VERSION "f33"

NS_ :

BS_:
BU_: RR RL FL FR GEN

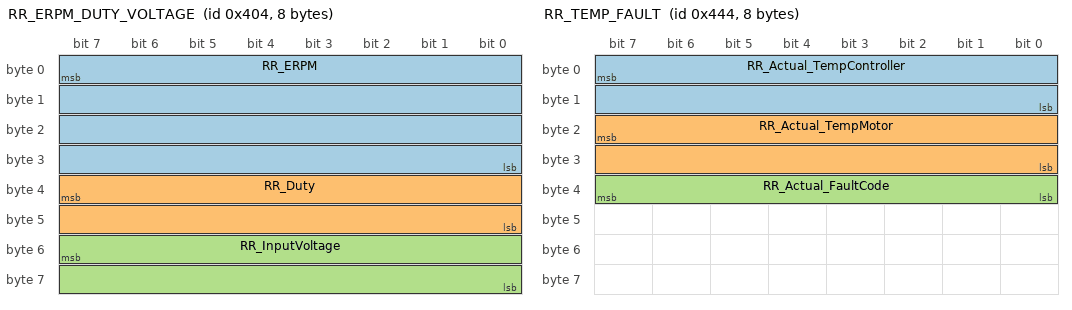
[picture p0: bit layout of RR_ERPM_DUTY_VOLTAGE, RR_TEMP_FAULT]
BO_ 1028 RR_ERPM_DUTY_VOLTAGE: 8 RR
 SG_ RR_ERPM : 7|32@0- (1,0) [-120000|120000] "rpm" Vector__XXX
 SG_ RR_Duty : 39|16@0- (0.1,0) [-100|100] "%" Vector__XXX
 SG_ RR_InputVoltage : 55|16@0- (1,0) [0|1000] "V" Vector__XXX

BO_ 1060 RR_AC_DC_CURRENT: 8 RR
 SG_ RR_AC_Current : 7|16@0- (0.1,0) [-850|850] "A"  Vector_XXX
 SG_ RR_DC_Current : 23|16@0- (0.1,0) [-850|850] "A"  Vector_XXX

BO_ 1092 RR_TEMP_FAULT: 8 RR
 SG_ RR_Actual_TempController : 7|16@0- (0.1,0) [-55|200] "C"  Vector__XXX
 SG_ RR_Actual_TempMotor : 23|16@0- (0.1,0) [-55|200] "C"  Vector__XXX
 SG_ RR_Actual_FaultCode : 39|8@0+ (1,0) [0|255] ""  Vector__XXX

BO_ 1124 RR_FOC : 8 RR
 SG_ RR_Actual_FOC_id : 7|32@0- (0.01,0) [-850|850] "Apk"  Vector__XXX
 SG_ RR_Actual_FOC_iq : 39|32@0- (0.01,0) [-850|850] "Apk"  Vector__XXX

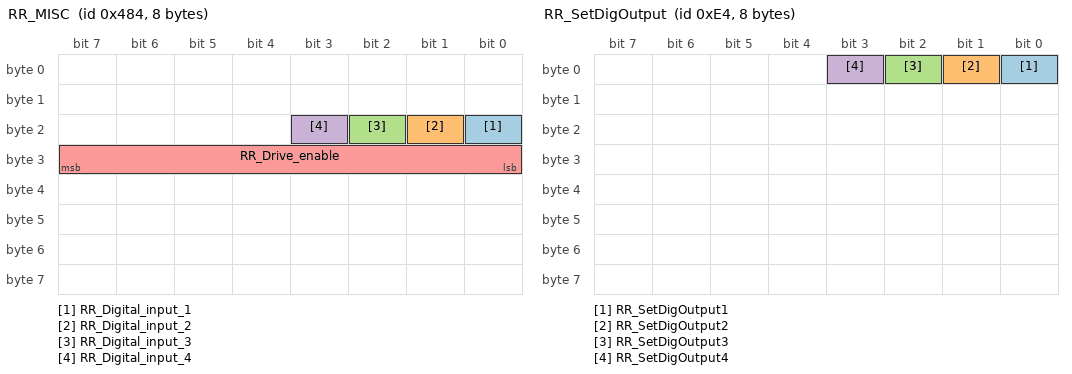
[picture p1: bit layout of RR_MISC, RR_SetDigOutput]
BO_ 1156 RR_MISC: 8 RR
 SG_ RR_Digital_input_1 : 16|1@0+ (1,0) [0|1] ""  Vector__XXX
 SG_ RR_Digital_input_2 : 17|1@0+ (1,0) [0|1] ""  Vector__XXX
 SG_ RR_Digital_input_3 : 18|1@0+ (1,0) [0|1] ""  Vector__XXX
 SG_ RR_Digital_input_4 : 19|1@0+ (1,0) [0|1] ""  Vector__XXX
 SG_ RR_Drive_enable : 31|8@0+ (1,0) [0|1] ""  Vector__XXX

BO_ 388 RR_ENABLE: 8 RR
 SG_ RR_DriveEnable : 7|8@0+ (1,0) [0|1] ""  Vector__XXX

BO_ 36 RR_SetAcCurrent: 8 RR
 SG_ RR_TargetAcCurrent : 7|16@0- (0.1,0) [-850|850] "A"  Vector__XXX

BO_ 68 RR_SetBrakeCurrent: 8 RR
 SG_ RR_TargetBrakeCurrent : 7|16@0- (0.1,0) [0|850] "A"  Vector__XXX

BO_ 100 RR_SetERPM: 4 RR
 SG_ RR_TargetSpeed : 7|32@0- (1,0) [-100000|100000] "ERPM"  Vector__XXX

BO_ 132 RR_SetPosition: 2 RR
 SG_ RR_TargetPosition : 7|16@0- (0.1,0) [0|359] "degree"  Vector__XXX

BO_ 164 RR_SetRelCurrent: 2 RR
 SG_ RR_TargetRelativeCurrent : 7|16@0- (0.1,0) [-100|100] "%"  Vector__XXX

BO_ 196 RR_SetRelBrakeCurrent: 2 RR
 SG_ RR_TargeRelativeBrakeCurrent : 7|16@0- (0.1,0) [0|100] "%"  Vector__XXX

BO_ 260 RR_SetMaxAcCurrent: 2 RR
 SG_ RR_MaxAcCurrent : 7|16@0- (0.1,0) [0|850] "A"  Vector__XXX

BO_ 292 RR_SetMaxAcBrakeCurrent: 2 RR
 SG_ RR_MaxAcBrakeCurrent : 7|16@0- (0.1,0) [-850|0] "A"  Vector__XXX

BO_ 324 RR_SetMaxDcCurrent: 2 RR
 SG_ RR_MaxDcCurrent : 7|16@0- (0.1,0) [0|850] "A"  Vector__XXX

BO_ 356 RR_SetMaxDcBrakeCurrent: 2 RR
 SG_ RR_MaxDcBrakeCurrent : 7|16@0- (0.1,0) [-850|0] "A"  Vector__XXX

BO_ 228 RR_SetDigOutput: 8 RR
 SG_ RR_SetDigOutput1 : 0|1@0+ (1,0) [0|1] "#" Vector__XXX
 SG_ RR_SetDigOutput2 : 1|1@0+ (1,0) [0|1] "#" Vector__XXX
 SG_ RR_SetDigOutput3 : 2|1@0+ (1,0) [0|1] "#" Vector__XXX
 SG_ RR_SetDigOutput4 : 3|1@0+ (1,0) [0|1] "#" Vector__XXX

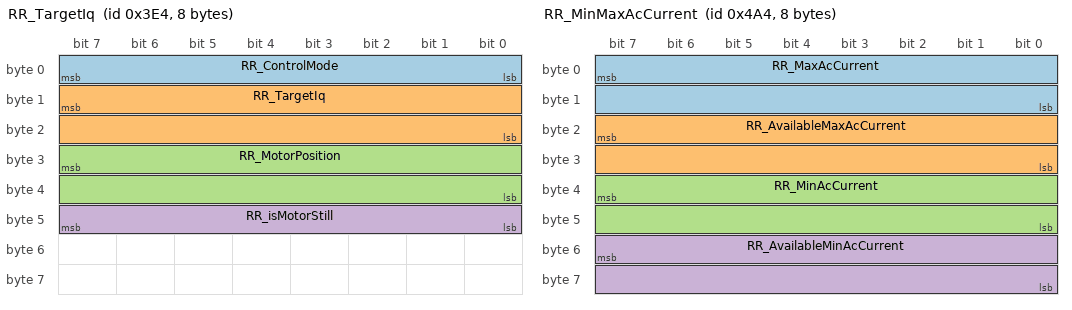
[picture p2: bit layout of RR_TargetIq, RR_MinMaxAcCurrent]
BO_ 996 RR_TargetIq: 8 RR
 SG_ RR_ControlMode : 7|8@0+ (1,0) [0|7] "#" Vector__XXX
 SG_ RR_TargetIq : 15|16@0- (0.1,0) [-850|850] "Apk" Vector__XXX
 SG_ RR_MotorPosition : 31|16@0+ (0.1,0) [0|359] "degree" Vector__XXX
 SG_ RR_isMotorStill : 47|8@0+ (1,0) [0|1] "#" Vector__XXX

BO_ 1188 RR_MinMaxAcCurrent: 8 RR
 SG_ RR_MaxAcCurrent : 7|16@0- (0.1,0) [0|850] "Apk" Vector__XXX
 SG_ RR_AvailableMaxAcCurrent : 23|16@0- (0.1,0) [0|850] "Apk" Vector__XXX
 SG_ RR_MinAcCurrent : 39|16@0- (0.1,0) [-850|0] "Apk" Vector__XXX
 SG_ RR_AvailableMinAcCurrent : 55|16@0- (0.1,0) [-850|0] "Apk" Vector__XXX

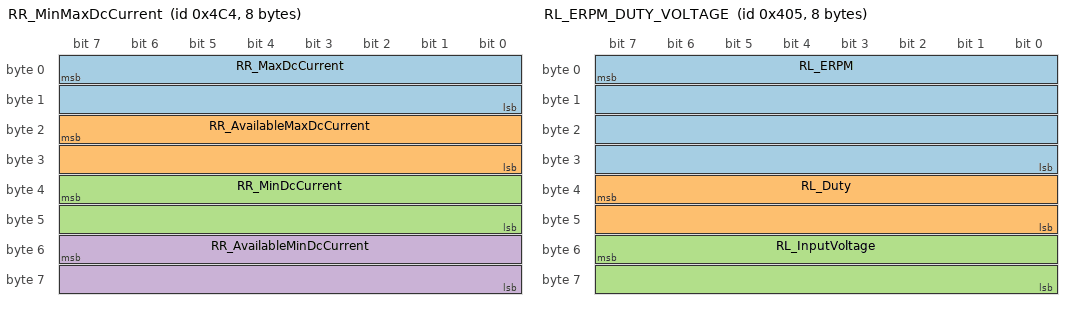
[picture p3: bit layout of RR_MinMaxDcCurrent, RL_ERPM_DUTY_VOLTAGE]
BO_ 1220 RR_MinMaxDcCurrent: 8 RR
 SG_ RR_MaxDcCurrent : 7|16@0- (0.1,0) [0|850] "Adc" Vector__XXX
 SG_ RR_AvailableMaxDcCurrent : 23|16@0- (0.1,0) [0|850] "Adc" Vector__XXX
 SG_ RR_MinDcCurrent : 39|16@0- (0.1,0) [-850|0] "Adc" Vector__XXX
 SG_ RR_AvailableMinDcCurrent : 55|16@0- (0.1,0) [-850|0] "Adc" Vector__XXX

BO_ 1029 RL_ERPM_DUTY_VOLTAGE: 8 RL
 SG_ RL_ERPM : 7|32@0- (1,0) [-120000|120000] "rpm" Vector__XXX
 SG_ RL_Duty : 39|16@0- (0.1,0) [-100|100] "%" Vector__XXX
 SG_ RL_InputVoltage : 55|16@0- (1,0) [0|1000] "V" Vector__XXX

BO_ 1061 RL_AC_DC_CURRENT: 8 RL
 SG_ RL_AC_Current : 7|16@0- (0.1,0) [-850|850] "A"  Vector_XXX
 SG_ RL_DC_Current : 23|16@0- (0.1,0) [-850|850] "A"  Vector_XXX

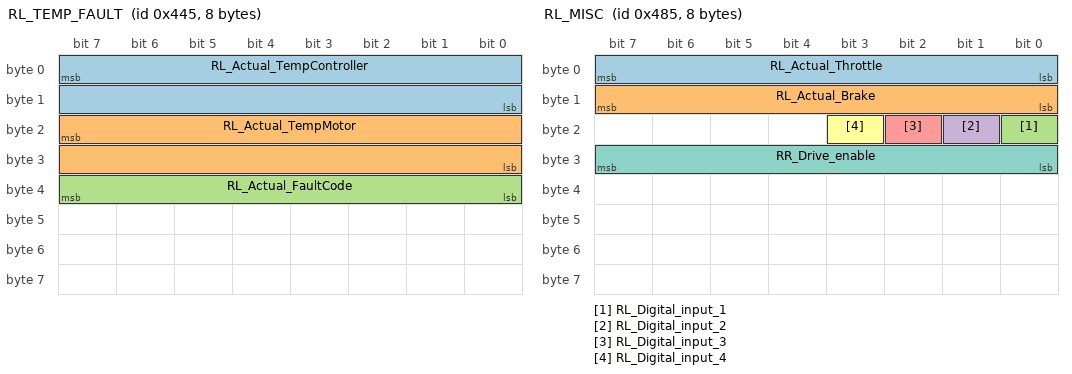
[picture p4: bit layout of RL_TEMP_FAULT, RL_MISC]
BO_ 1093 RL_TEMP_FAULT: 8 RL
 SG_ RL_Actual_TempController : 7|16@0- (0.1,0) [-55|200] "C"  Vector__XXX
 SG_ RL_Actual_TempMotor : 23|16@0- (0.1,0) [-55|200] "C"  Vector__XXX
 SG_ RL_Actual_FaultCode : 39|8@0+ (1,0) [0|255] ""  Vector__XXX

BO_ 1125 RL_FOC : 8 RL
 SG_ RL_Actual_FOC_id : 7|32@0- (0.01,0) [-850|850] "Apk"  Vector__XXX
 SG_ RL_Actual_FOC_iq : 39|32@0- (0.01,0) [-850|850] "Apk"  Vector__XXX

BO_ 1157 RL_MISC: 8 RL
 SG_ RL_Actual_Throttle : 7|8@0- (1,0) [0|100] "%"  Vector__XXX
 SG_ RL_Actual_Brake : 15|8@0- (1,0) [0|100] "%"  Vector__XXX
 SG_ RL_Digital_input_1 : 16|1@0+ (1,0) [0|1] ""  Vector__XXX
 SG_ RL_Digital_input_2 : 17|1@0+ (1,0) [0|1] ""  Vector__XXX
 SG_ RL_Digital_input_3 : 18|1@0+ (1,0) [0|1] ""  Vector__XXX
 SG_ RL_Digital_input_4 : 19|1@0+ (1,0) [0|1] ""  Vector__XXX
 SG_ RR_Drive_enable : 31|8@0+ (1,0) [0|1] ""  Vector__XXX

BO_ 389 RL_ENABLE: 8 RL
 SG_ RL_DriveEnable : 7|8@0+ (1,0) [0|1] ""  Vector__XXX

BO_ 37 RL_SetAcCurrent: 8 RL
 SG_ RL_TargetAcCurrent : 7|16@0- (0.1,0) [-850|850] "A"  Vector__XXX

BO_ 69 RL_SetBrakeCurrent: 8 RL
 SG_ RL_TargetBrakeCurrent : 7|16@0- (0.1,0) [0|850] "A"  Vector__XXX

BO_ 101 RL_SetERPM: 4 RL
 SG_ RL_TargetSpeed : 7|32@0- (1,0) [-100000|100000] "ERPM"  Vector__XXX

BO_ 133 RL_SetPosition: 2 RL
 SG_ RL_TargetPosition : 7|16@0- (0.1,0) [0|359] "degree"  Vector__XXX

BO_ 165 RL_SetRelCurrent: 2 RL
 SG_ RL_TargetRelativeCurrent : 7|16@0- (0.1,0) [-100|100] "%"  Vector__XXX

BO_ 197 RL_SetRelBrakeCurrent: 2 RL
 SG_ RL_TargeRelativeBrakeCurrent : 7|16@0- (0.1,0) [0|100] "%"  Vector__XXX

BO_ 261 RL_SetMaxAcCurrent: 2 RL
 SG_ RL_MaxAcCurrent : 7|16@0- (0.1,0) [0|850] "A"  Vector__XXX

BO_ 293 RL_SetMaxAcBrakeCurrent: 2 RL
 SG_ RL_MaxAcBrakeCurrent : 7|16@0- (0.1,0) [-850|0] "A"  Vector__XXX

BO_ 325 RL_SetMaxDcCurrent: 2 RL
 SG_ RL_MaxDcCurrent : 7|16@0- (0.1,0) [0|850] "A"  Vector__XXX

BO_ 357 RL_SetMaxDcBrakeCurrent: 2 RL
 SG_ RL_MaxDcBrakeCurrent : 7|16@0- (0.1,0) [-850|0] "A"  Vector__XXX

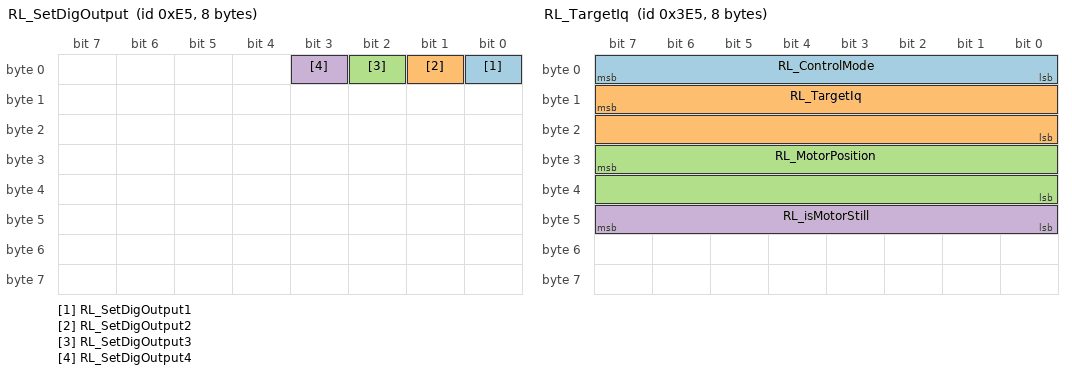
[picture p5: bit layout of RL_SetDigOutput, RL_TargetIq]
BO_ 229 RL_SetDigOutput: 8 RL
 SG_ RL_SetDigOutput1 : 0|1@0+ (1,0) [0|1] "#" Vector__XXX
 SG_ RL_SetDigOutput2 : 1|1@0+ (1,0) [0|1] "#" Vector__XXX
 SG_ RL_SetDigOutput3 : 2|1@0+ (1,0) [0|1] "#" Vector__XXX
 SG_ RL_SetDigOutput4 : 3|1@0+ (1,0) [0|1] "#" Vector__XXX

BO_ 997 RL_TargetIq: 8 RL
 SG_ RL_ControlMode : 7|8@0+ (1,0) [0|7] "#" Vector__XXX
 SG_ RL_TargetIq : 15|16@0- (0.1,0) [-850|850] "Apk" Vector__XXX
 SG_ RL_MotorPosition : 31|16@0+ (0.1,0) [0|359] "degree" Vector__XXX
 SG_ RL_isMotorStill : 47|8@0+ (1,0) [0|1] "#" Vector__XXX

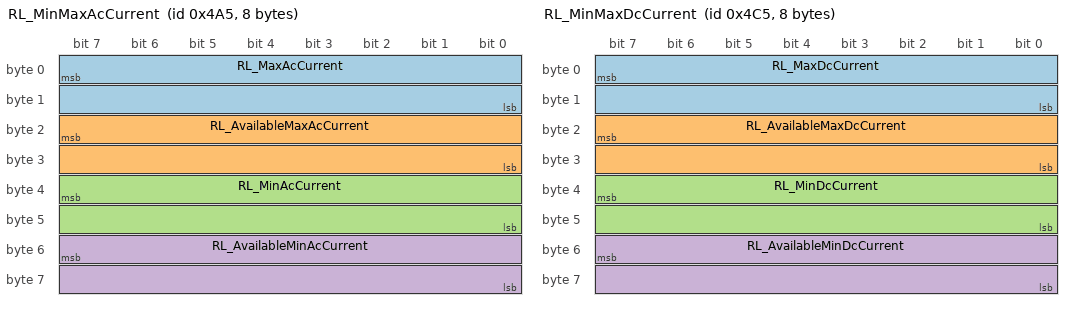
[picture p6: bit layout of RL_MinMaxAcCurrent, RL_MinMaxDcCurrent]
BO_ 1189 RL_MinMaxAcCurrent: 8 RL
 SG_ RL_MaxAcCurrent : 7|16@0- (0.1,0) [0|850] "Apk" Vector__XXX
 SG_ RL_AvailableMaxAcCurrent : 23|16@0- (0.1,0) [0|850] "Apk" Vector__XXX
 SG_ RL_MinAcCurrent : 39|16@0- (0.1,0) [-850|0] "Apk" Vector__XXX
 SG_ RL_AvailableMinAcCurrent : 55|16@0- (0.1,0) [-850|0] "Apk" Vector__XXX

BO_ 1221 RL_MinMaxDcCurrent: 8 RL
 SG_ RL_MaxDcCurrent : 7|16@0- (0.1,0) [0|850] "Adc" Vector__XXX
 SG_ RL_AvailableMaxDcCurrent : 23|16@0- (0.1,0) [0|850] "Adc" Vector__XXX
 SG_ RL_MinDcCurrent : 39|16@0- (0.1,0) [-850|0] "Adc" Vector__XXX
 SG_ RL_AvailableMinDcCurrent : 55|16@0- (0.1,0) [-850|0] "Adc" Vector__XXX

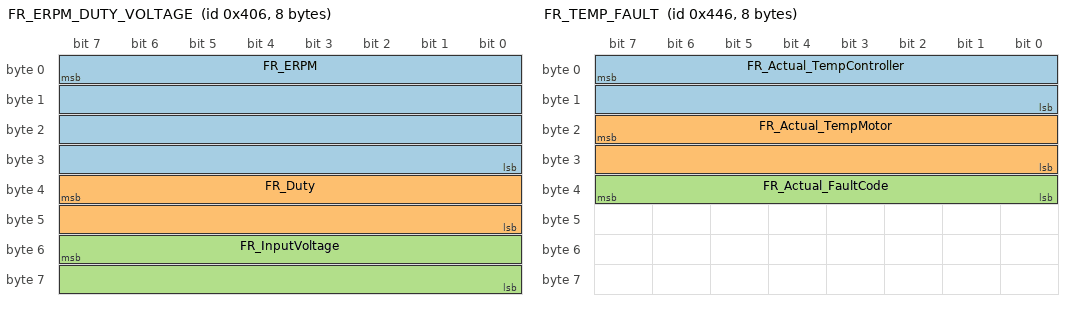
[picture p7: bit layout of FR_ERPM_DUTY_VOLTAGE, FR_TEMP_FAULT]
BO_ 1030 FR_ERPM_DUTY_VOLTAGE: 8 FR
 SG_ FR_ERPM : 7|32@0- (1,0) [-120000|120000] "rpm" Vector__XXX
 SG_ FR_Duty : 39|16@0- (0.1,0) [-100|100] "%" Vector__XXX
 SG_ FR_InputVoltage : 55|16@0- (1,0) [0|1000] "V" Vector__XXX

BO_ 1062 FR_AC_DC_CURRENT: 8 FR
 SG_ FR_AC_Current : 7|16@0- (0.1,0) [-850|850] "A"  Vector_XXX
 SG_ FR_DC_Current : 23|16@0- (0.1,0) [-850|850] "A"  Vector_XXX

BO_ 1094 FR_TEMP_FAULT: 8 FR
 SG_ FR_Actual_TempController : 7|16@0- (0.1,0) [-55|200] "C"  Vector__XXX
 SG_ FR_Actual_TempMotor : 23|16@0- (0.1,0) [-55|200] "C"  Vector__XXX
 SG_ FR_Actual_FaultCode : 39|8@0+ (1,0) [0|255] ""  Vector__XXX

BO_ 1126 FR_FOC : 8 FR
 SG_ FR_Actual_FOC_id : 7|32@0- (0.01,0) [-850|850] "Apk"  Vector__XXX
 SG_ FR_Actual_FOC_iq : 39|32@0- (0.01,0) [-850|850] "Apk"  Vector__XXX

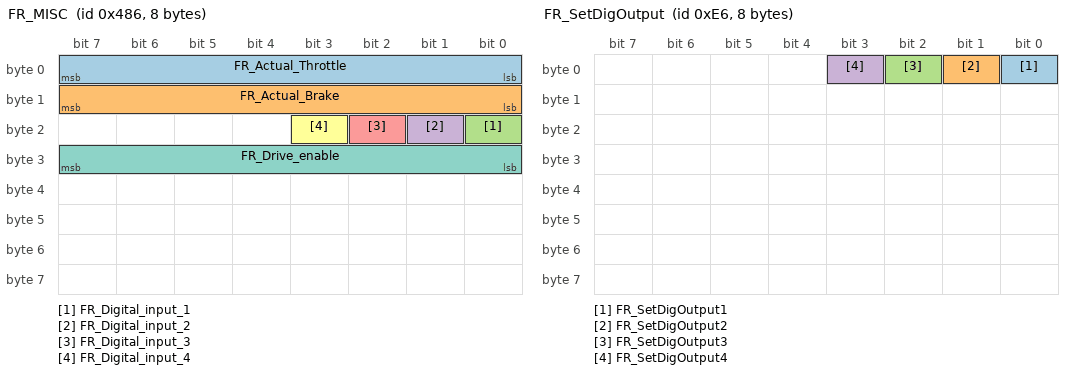
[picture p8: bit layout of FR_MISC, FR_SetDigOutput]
BO_ 1158 FR_MISC: 8 FR
 SG_ FR_Actual_Throttle : 7|8@0- (1,0) [0|100] "%"  Vector__XXX
 SG_ FR_Actual_Brake : 15|8@0- (1,0) [0|100] "%"  Vector__XXX
 SG_ FR_Digital_input_1 : 16|1@0+ (1,0) [0|1] ""  Vector__XXX
 SG_ FR_Digital_input_2 : 17|1@0+ (1,0) [0|1] ""  Vector__XXX
 SG_ FR_Digital_input_3 : 18|1@0+ (1,0) [0|1] ""  Vector__XXX
 SG_ FR_Digital_input_4 : 19|1@0+ (1,0) [0|1] ""  Vector__XXX
 SG_ FR_Drive_enable : 31|8@0+ (1,0) [0|1] ""  Vector__XXX

BO_ 390 FR_ENABLE: 8 FR
 SG_ FR_DriveEnable : 7|8@0+ (1,0) [0|1] ""  Vector__XXX

BO_ 38 FR_SetAcCurrent: 8 FR
 SG_ FR_TargetAcCurrent : 7|16@0- (0.1,0) [-850|850] "A"  Vector__XXX

BO_ 70 FR_SetBrakeCurrent: 8 FR
 SG_ FR_TargetBrakeCurrent : 7|16@0- (0.1,0) [0|850] "A"  Vector__XXX

BO_ 102 FR_SetERPM: 4 FR
 SG_ FR_TargetSpeed : 7|32@0- (1,0) [-100000|100000] "ERPM"  Vector__XXX

BO_ 134 FR_SetPosition: 2 FR
 SG_ FR_TargetPosition : 7|16@0- (0.1,0) [0|359] "degree"  Vector__XXX

BO_ 166 FR_SetRelCurrent: 2 FR
 SG_ FR_TargetRelativeCurrent : 7|16@0- (0.1,0) [-100|100] "%"  Vector__XXX

BO_ 198 FR_SetRelBrakeCurrent: 2 FR
 SG_ FR_TargeRelativeBrakeCurrent : 7|16@0- (0.1,0) [0|100] "%"  Vector__XXX

BO_ 262 FR_SetMaxAcCurrent: 2 FR
 SG_ FR_MaxAcCurrent : 7|16@0- (0.1,0) [0|850] "A"  Vector__XXX

BO_ 294 FR_SetMaxAcBrakeCurrent: 2 FR
 SG_ FR_MaxAcBrakeCurrent : 7|16@0- (0.1,0) [-850|0] "A"  Vector__XXX

BO_ 326 FR_SetMaxDcCurrent: 2 FR
 SG_ FR_MaxDcCurrent : 7|16@0- (0.1,0) [0|850] "A"  Vector__XXX

BO_ 358 FR_SetMaxDcBrakeCurrent: 2 FR
 SG_ FR_MaxDcBrakeCurrent : 7|16@0- (0.1,0) [-850|0] "A"  Vector__XXX

BO_ 230 FR_SetDigOutput: 8 FR
 SG_ FR_SetDigOutput1 : 0|1@0+ (1,0) [0|1] "#" Vector__XXX
 SG_ FR_SetDigOutput2 : 1|1@0+ (1,0) [0|1] "#" Vector__XXX
 SG_ FR_SetDigOutput3 : 2|1@0+ (1,0) [0|1] "#" Vector__XXX
 SG_ FR_SetDigOutput4 : 3|1@0+ (1,0) [0|1] "#" Vector__XXX

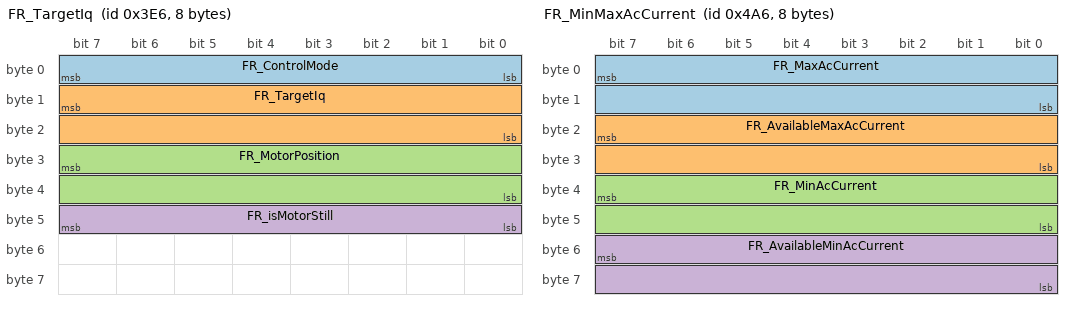
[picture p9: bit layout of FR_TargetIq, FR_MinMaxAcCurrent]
BO_ 998 FR_TargetIq: 8 FR
 SG_ FR_ControlMode : 7|8@0+ (1,0) [0|7] "#" Vector__XXX
 SG_ FR_TargetIq : 15|16@0- (0.1,0) [-850|850] "Apk" Vector__XXX
 SG_ FR_MotorPosition : 31|16@0+ (0.1,0) [0|359] "degree" Vector__XXX
 SG_ FR_isMotorStill : 47|8@0+ (1,0) [0|1] "#" Vector__XXX

BO_ 1190 FR_MinMaxAcCurrent: 8 FR
 SG_ FR_MaxAcCurrent : 7|16@0- (0.1,0) [0|850] "Apk" Vector__XXX
 SG_ FR_AvailableMaxAcCurrent : 23|16@0- (0.1,0) [0|850] "Apk" Vector__XXX
 SG_ FR_MinAcCurrent : 39|16@0- (0.1,0) [-850|0] "Apk" Vector__XXX
 SG_ FR_AvailableMinAcCurrent : 55|16@0- (0.1,0) [-850|0] "Apk" Vector__XXX

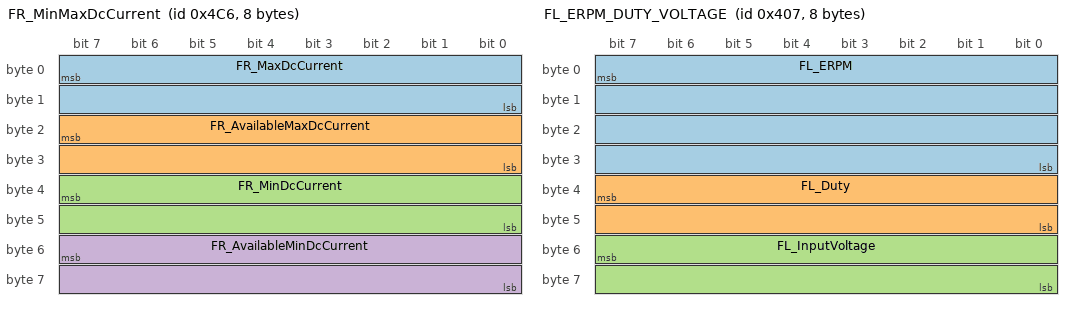
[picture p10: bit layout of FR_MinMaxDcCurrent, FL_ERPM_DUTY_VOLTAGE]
BO_ 1222 FR_MinMaxDcCurrent: 8 FR
 SG_ FR_MaxDcCurrent : 7|16@0- (0.1,0) [0|850] "Adc" Vector__XXX
 SG_ FR_AvailableMaxDcCurrent : 23|16@0- (0.1,0) [0|850] "Adc" Vector__XXX
 SG_ FR_MinDcCurrent : 39|16@0- (0.1,0) [-850|0] "Adc" Vector__XXX
 SG_ FR_AvailableMinDcCurrent : 55|16@0- (0.1,0) [-850|0] "Adc" Vector__XXX

BO_ 1031 FL_ERPM_DUTY_VOLTAGE: 8 FL
 SG_ FL_ERPM : 7|32@0- (1,0) [-120000|120000] "rpm" Vector__XXX
 SG_ FL_Duty : 39|16@0- (0.1,0) [-100|100] "%" Vector__XXX
 SG_ FL_InputVoltage : 55|16@0- (1,0) [0|1000] "V" Vector__XXX

BO_ 1063 FL_AC_DC_CURRENT: 8 FL
 SG_ FL_AC_Current : 7|16@0- (0.1,0) [-850|850] "A"  Vector_XXX
 SG_ FL_DC_Current : 23|16@0- (0.1,0) [-850|850] "A"  Vector_XXX

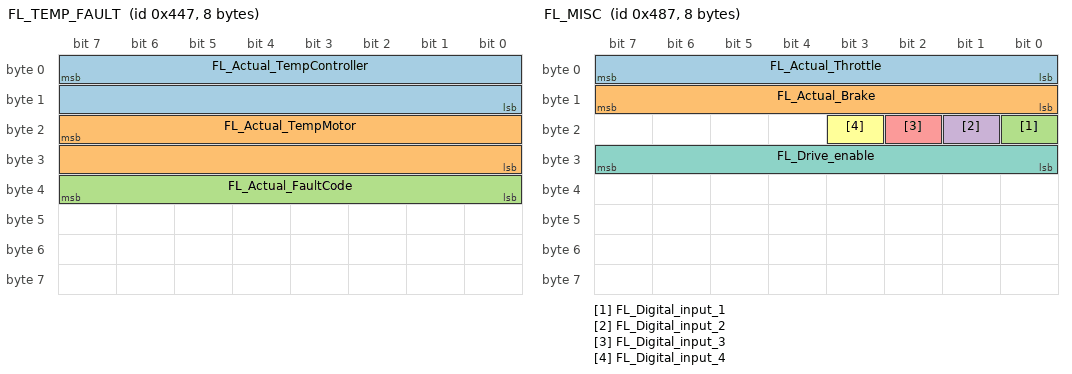
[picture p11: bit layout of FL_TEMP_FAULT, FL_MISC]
BO_ 1095 FL_TEMP_FAULT: 8 FL
 SG_ FL_Actual_TempController : 7|16@0- (0.1,0) [-55|200] "C"  Vector__XXX
 SG_ FL_Actual_TempMotor : 23|16@0- (0.1,0) [-55|200] "C"  Vector__XXX
 SG_ FL_Actual_FaultCode : 39|8@0+ (1,0) [0|255] ""  Vector__XXX

BO_ 1127 FL_FOC : 8 FL
 SG_ FL_Actual_FOC_id : 7|32@0- (0.01,0) [-850|850] "Apk"  Vector__XXX
 SG_ FL_Actual_FOC_iq : 39|32@0- (0.01,0) [-850|850] "Apk"  Vector__XXX

BO_ 1159 FL_MISC: 8 FL
 SG_ FL_Actual_Throttle : 7|8@0- (1,0) [0|100] "%"  Vector__XXX
 SG_ FL_Actual_Brake : 15|8@0- (1,0) [0|100] "%"  Vector__XXX
 SG_ FL_Digital_input_1 : 16|1@0+ (1,0) [0|1] ""  Vector__XXX
 SG_ FL_Digital_input_2 : 17|1@0+ (1,0) [0|1] ""  Vector__XXX
 SG_ FL_Digital_input_3 : 18|1@0+ (1,0) [0|1] ""  Vector__XXX
 SG_ FL_Digital_input_4 : 19|1@0+ (1,0) [0|1] ""  Vector__XXX
 SG_ FL_Drive_enable : 31|8@0+ (1,0) [0|1] ""  Vector__XXX

BO_ 391 FL_ENABLE: 8 FL
 SG_ FL_DriveEnable : 7|8@0+ (1,0) [0|1] ""  Vector__XXX

BO_ 39 FL_SetAcCurrent: 8 RL
 SG_ FL_TargetAcCurrent : 7|16@0- (0.1,0) [-850|850] "A"  Vector__XXX

BO_ 71 FL_SetBrakeCurrent: 8 FL
 SG_ FL_TargetBrakeCurrent : 7|16@0- (0.1,0) [0|850] "A"  Vector__XXX

BO_ 103 FL_SetERPM: 4 FL
 SG_ FL_TargetSpeed : 7|32@0- (1,0) [-100000|100000] "ERPM"  Vector__XXX

BO_ 135 FL_SetPosition: 2 FL
 SG_ FL_TargetPosition : 7|16@0- (0.1,0) [0|359] "degree"  Vector__XXX

BO_ 167 FL_SetRelCurrent: 2 FL
 SG_ FL_TargetRelativeCurrent : 7|16@0- (0.1,0) [-100|100] "%"  Vector__XXX

BO_ 199 FL_SetRelBrakeCurrent: 2 FL
 SG_ FL_TargeRelativeBrakeCurrent : 7|16@0- (0.1,0) [0|100] "%"  Vector__XXX

BO_ 263 FL_SetMaxAcCurrent: 2 FL
 SG_ FL_MaxAcCurrent : 7|16@0- (0.1,0) [0|850] "A"  Vector__XXX

BO_ 295 FL_SetMaxAcBrakeCurrent: 2 FL
 SG_ FL_MaxAcBrakeCurrent : 7|16@0- (0.1,0) [-850|0] "A"  Vector__XXX

BO_ 327 FL_SetMaxDcCurrent: 2 FL
 SG_ FL_MaxDcCurrent : 7|16@0- (0.1,0) [0|850] "A"  Vector__XXX

BO_ 359 FL_SetMaxDcBrakeCurrent: 2 FL
 SG_ FL_MaxDcBrakeCurrent : 7|16@0- (0.1,0) [-850|0] "A"  Vector__XXX

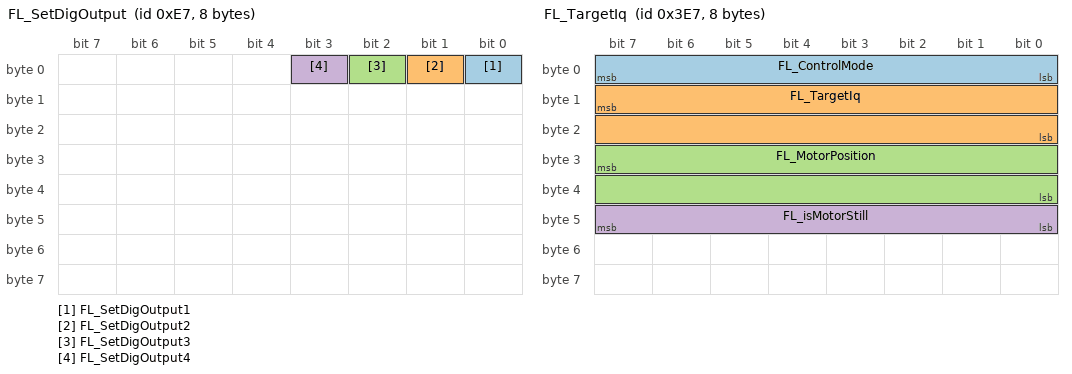
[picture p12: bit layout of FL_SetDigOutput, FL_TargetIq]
BO_ 231 FL_SetDigOutput: 8 FL
 SG_ FL_SetDigOutput1 : 0|1@0+ (1,0) [0|1] "#" Vector__XXX
 SG_ FL_SetDigOutput2 : 1|1@0+ (1,0) [0|1] "#" Vector__XXX
 SG_ FL_SetDigOutput3 : 2|1@0+ (1,0) [0|1] "#" Vector__XXX
 SG_ FL_SetDigOutput4 : 3|1@0+ (1,0) [0|1] "#" Vector__XXX

BO_ 999 FL_TargetIq: 8 FL
 SG_ FL_ControlMode : 7|8@0+ (1,0) [0|7] "#" Vector__XXX
 SG_ FL_TargetIq : 15|16@0- (0.1,0) [-850|850] "Apk" Vector__XXX
 SG_ FL_MotorPosition : 31|16@0+ (0.1,0) [0|359] "degree" Vector__XXX
 SG_ FL_isMotorStill : 47|8@0+ (1,0) [0|1] "#" Vector__XXX

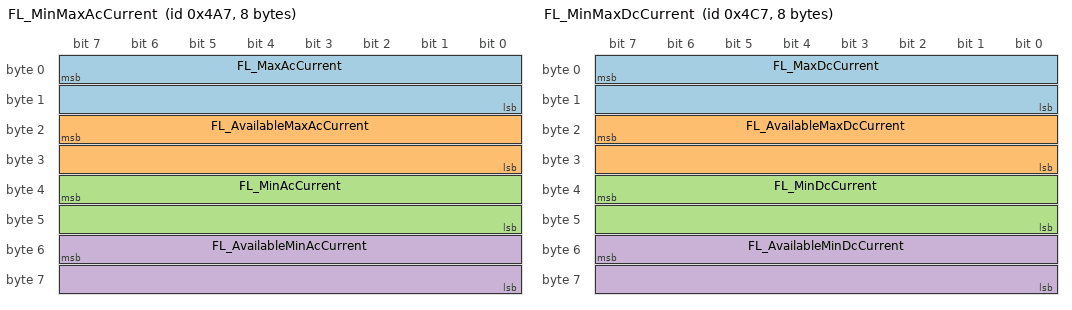
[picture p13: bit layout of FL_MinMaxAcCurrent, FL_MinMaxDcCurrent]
BO_ 1191 FL_MinMaxAcCurrent: 8 FL
 SG_ FL_MaxAcCurrent : 7|16@0- (0.1,0) [0|850] "Apk" Vector__XXX
 SG_ FL_AvailableMaxAcCurrent : 23|16@0- (0.1,0) [0|850] "Apk" Vector__XXX
 SG_ FL_MinAcCurrent : 39|16@0- (0.1,0) [-850|0] "Apk" Vector__XXX
 SG_ FL_AvailableMinAcCurrent : 55|16@0- (0.1,0) [-850|0] "Apk" Vector__XXX

BO_ 1223 FL_MinMaxDcCurrent: 8 FL
 SG_ FL_MaxDcCurrent : 7|16@0- (0.1,0) [0|850] "Adc" Vector__XXX
 SG_ FL_AvailableMaxDcCurrent : 23|16@0- (0.1,0) [0|850] "Adc" Vector__XXX
 SG_ FL_MinDcCurrent : 39|16@0- (0.1,0) [-850|0] "Adc" Vector__XXX
 SG_ FL_AvailableMinDcCurrent : 55|16@0- (0.1,0) [-850|0] "Adc" Vector__XXX

CM_ "Dummy messages for use in the C files. These will never be sent over CAN,
    it is only to make the C code more generic";

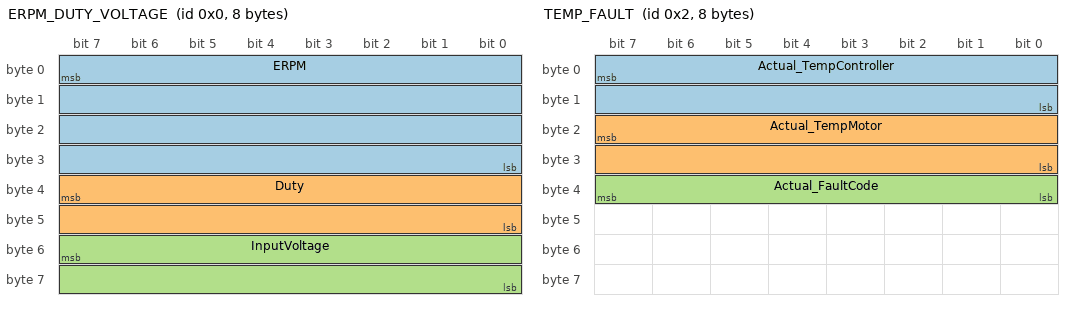
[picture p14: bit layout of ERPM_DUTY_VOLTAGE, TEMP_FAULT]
BO_ 000 ERPM_DUTY_VOLTAGE: 8 GEN
 SG_ ERPM : 7|32@0- (1,0) [-120000|120000] "rpm" Vector__XXX
 SG_ Duty : 39|16@0- (0.1,0) [-100|100] "%" Vector__XXX
 SG_ InputVoltage : 55|16@0- (1,0) [0|1000] "V" Vector__XXX

BO_ 001 AC_DC_CURRENT: 8 GEN
 SG_ AC_Current : 7|16@0- (0.1,0) [-850|850] "A"  Vector_XXX
 SG_ DC_Current : 23|16@0- (0.1,0) [-850|850] "A"  Vector_XXX

BO_ 002 TEMP_FAULT: 8 GEN
 SG_ Actual_TempController : 7|16@0- (0.1,0) [-55|200] "C"  Vector__XXX
 SG_ Actual_TempMotor : 23|16@0- (0.1,0) [-55|200] "C"  Vector__XXX
 SG_ Actual_FaultCode : 39|8@0+ (1,0) [0|255] ""  Vector__XXX

BO_ 003 FOC: 8 GEN
 SG_ Actual_FOC_id : 7|32@0- (0.01,0) [-850|850] "Apk"  Vector__XXX
 SG_ Actual_FOC_iq : 39|32@0- (0.01,0) [-850|850] "Apk"  Vector__XXX

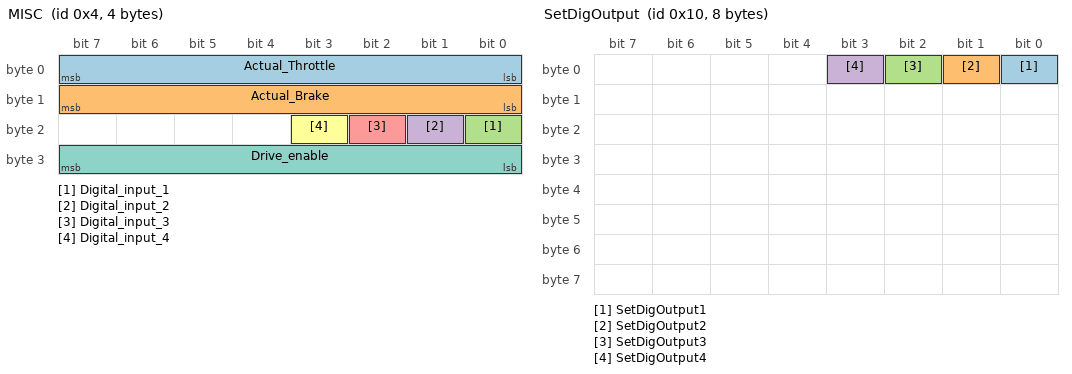
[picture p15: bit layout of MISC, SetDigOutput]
BO_ 004 MISC: 4 GEN
 SG_ Actual_Throttle : 7|8@0- (1,0) [0|100] "%"  HV500_commands
 SG_ Actual_Brake : 15|8@0- (1,0) [0|100] "%"  HV500_commands
 SG_ Digital_input_1 : 16|1@0+ (1,0) [0|1] ""  HV500_commands
 SG_ Digital_input_2 : 17|1@0+ (1,0) [0|1] ""  HV500_commands
 SG_ Digital_input_3 : 18|1@0+ (1,0) [0|1] ""  HV500_commands
 SG_ Digital_input_4 : 19|1@0+ (1,0) [0|1] ""  HV500_commands
 SG_ Drive_enable : 31|8@0+ (1,0) [0|1] ""  HV500_commands

BO_ 005 ENABLE: 8 GEN
 SG_ DriveEnable : 7|8@0+ (1,0) [0|1] ""  Vector__XXX

BO_ 006 SetAcCurrent: 8 GEN
 SG_ TargetAcCurrent : 7|16@0- (0.1,0) [-850|850] "A"  Vector__XXX

BO_ 007 SetBrakeCurrent: 8 GEN
 SG_ TargetBrakeCurrent : 7|16@0- (0.1,0) [0|850] "A"  Vector__XXX

BO_ 008 SetERPM: 4 GEN
 SG_ TargetSpeed : 7|32@0- (1,0) [-100000|100000] "ERPM"  Vector__XXX

BO_ 009 SetPosition: 2 GEN
 SG_ TargetPosition : 7|16@0- (0.1,0) [0|359] "degree"  Vector__XXX

BO_ 010 SetRelCurrent: 2 GEN
 SG_ TargetRelativeCurrent : 7|16@0- (0.1,0) [-100|100] "%"  Vector__XXX

BO_ 011 SetRelBrakeCurrent: 2 GEN
 SG_ TargeRelativeBrakeCurrent : 7|16@0- (0.1,0) [0|100] "%"  Vector__XXX

BO_ 012 SetMaxAcCurrent: 2 GEN
 SG_ MaxAcCurrent : 7|16@0- (0.1,0) [0|850] "A"  Vector__XXX

BO_ 013 SetMaxAcBrakeCurrent: 2 GEN
 SG_ MaxAcBrakeCurrent : 7|16@0- (0.1,0) [-850|0] "A"  Vector__XXX

BO_ 014 SetMaxDcCurrent: 2 GEN
 SG_ MaxDcCurrent : 7|16@0- (0.1,0) [0|850] "A"  Vector__XXX

BO_ 015 SetMaxDcBrakeCurrent: 2 GEN
 SG_ MaxDcBrakeCurrent : 7|16@0- (0.1,0) [-850|0] "A"  Vector__XXX

BO_ 016 SetDigOutput: 8 GEN
 SG_ SetDigOutput1 : 0|1@0+ (1,0) [0|1] "#" Vector__XXX
 SG_ SetDigOutput2 : 1|1@0+ (1,0) [0|1] "#" Vector__XXX
 SG_ SetDigOutput3 : 2|1@0+ (1,0) [0|1] "#" Vector__XXX
 SG_ SetDigOutput4 : 3|1@0+ (1,0) [0|1] "#" Vector__XXX

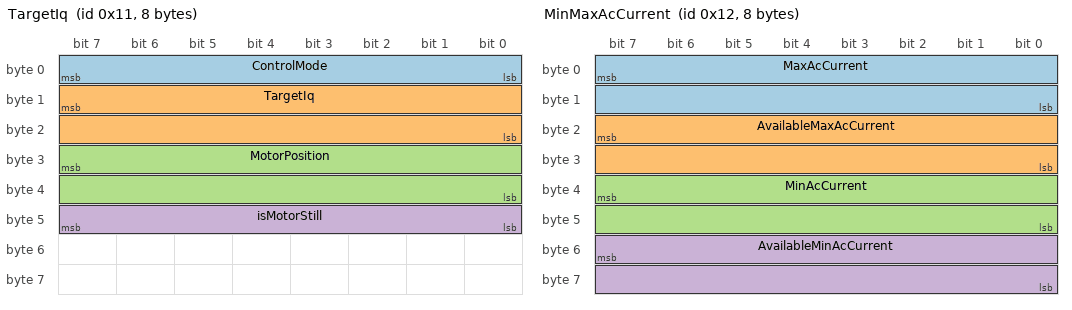
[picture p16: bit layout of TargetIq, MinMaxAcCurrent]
BO_ 017 TargetIq: 8 GEN
 SG_ ControlMode : 7|8@0+ (1,0) [0|7] "#" Vector__XXX
 SG_ TargetIq : 15|16@0- (0.1,0) [-850|850] "Apk" Vector__XXX
 SG_ MotorPosition : 31|16@0+ (0.1,0) [0|359] "degree" Vector__XXX
 SG_ isMotorStill : 47|8@0+ (1,0) [0|1] "#" Vector__XXX

BO_ 018 MinMaxAcCurrent: 8 GEN
 SG_ MaxAcCurrent : 7|16@0- (0.1,0) [0|850] "Apk" Vector__XXX
 SG_ AvailableMaxAcCurrent : 23|16@0- (0.1,0) [0|850] "Apk" Vector__XXX
 SG_ MinAcCurrent : 39|16@0- (0.1,0) [-850|0] "Apk" Vector__XXX
 SG_ AvailableMinAcCurrent : 55|16@0- (0.1,0) [-850|0] "Apk" Vector__XXX

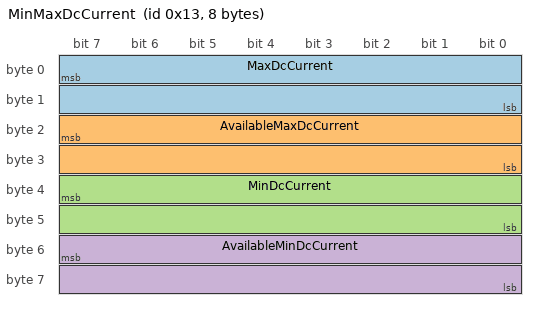
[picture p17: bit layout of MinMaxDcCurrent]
BO_ 019 MinMaxDcCurrent: 8 GEN
 SG_ MaxDcCurrent : 7|16@0- (0.1,0) [0|850] "Adc" Vector__XXX
 SG_ AvailableMaxDcCurrent : 23|16@0- (0.1,0) [0|850] "Adc" Vector__XXX
 SG_ MinDcCurrent : 39|16@0- (0.1,0) [-850|0] "Adc" Vector__XXX
 SG_ AvailableMinDcCurrent : 55|16@0- (0.1,0) [-850|0] "Adc" Vector__XXX
